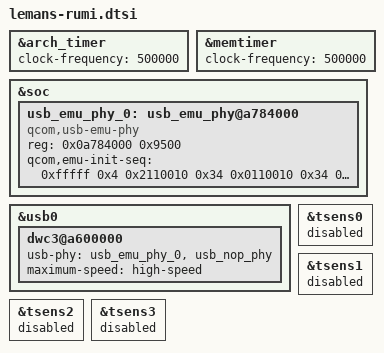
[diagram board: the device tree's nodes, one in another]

&arch_timer {
	clock-frequency = <500000>;
};

&memtimer {
	clock-frequency = <500000>;
};

&soc {
};

&soc {
	usb_emu_phy_0: usb_emu_phy@a784000 {
		compatible = "qcom,usb-emu-phy";
		reg = <0x0a784000 0x9500>;

		qcom,emu-init-seq = <0xfffff 0x4
				     0x2110010 0x34
				     0x0110010 0x34
				     0xffff3 0x4
				     0xffff0 0x4
				     0x100000 0x20
				     0x0 0x20
				     0x1A0 0x20
				     0x100000 0x3c
				     0x0 0x3c
				     0x10060 0x3c
				     0x0 0x4
				     0x9 0x14>;
	};
};

&usb0 {
	dwc3@a600000 {
		usb-phy = <&usb_emu_phy_0>, <&usb_nop_phy>;
		maximum-speed = "high-speed";
	};
};

&tsens0 {
		status = "disabled";
};

&tsens1 {
		status = "disabled";
};

&tsens2 {
		status = "disabled";
};

&tsens3 {
		status = "disabled";
};
